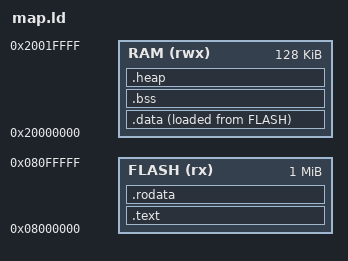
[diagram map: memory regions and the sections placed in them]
/*
 * ============================================================================
 * LINKER SCRIPT FOR BARE-METAL STM32F407 C++ OPENPLC HARDWARE
 * ============================================================================
 */

/* Entry Point definition: Instructs the toolchain where execution starts at boot */
/*ENTRY(Reset_Handler)*/

/* Specify the physical memory layout of the STM32F407VGT6 microcontroller :
 * 1. FLASH (rx) : Read-Only and Executable memory. Holds your code, constants, and tables.
 * 2. RAM (rwx)   : Read-Write and Executable memory. Holds global variables, stack, and heap.
 */
MEMORY
{
  FLASH (rx)      : ORIGIN = 0x08000000, LENGTH = 1024K
  RAM (rwx)       : ORIGIN = 0x20000000, LENGTH = 128K
}

SECTIONS
{
  /* 
   * ==========================================================================
   * 1. THE EXECUTABLE CODE SECTION (.text)
   * ==========================================================================
   * This section targets FLASH memory. It must strictly contain executable
   * code patterns to avoid security / MPU faults if Execute-Only permissions are enforced.
   */
  .text :
  {
    . = ALIGN(4); /* Pads memory layout to align perfectly with the 32-bit hardware bus */
    
    /* The Vector Table MUST sit at the very front of Flash memory (Address 0x08000000) */
    *(.vectors*) 
    
    /* Main application machine code compiled from all your .cpp assembly pools */
    *(.text*) 
    
    . = ALIGN(4);
  } > FLASH

  /* 
   * ==========================================================================
   * 2. THE READ-ONLY DATA SECTION (.rodata)
   * ==========================================================================
   * This section isolates data variables from code blocks, making it highly secure.
   */
  .rodata :
  {
    . = ALIGN(4);
    
    /* Holds string literals, constant structures, and look-up parameters */
    *(.rodata*) 
    
    /*
     * ------------------------------------------------------------------------
     * C++ RUNTIME OBJECT CONSTRUCTOR ARRAYS (CRITICAL FOR OPENPLC)
     * ------------------------------------------------------------------------
     * When your startup.s file executes 'BL __libc_init_array', the routine loops
     * through the addresses bounded between '__init_array_start' and '__init_array_end'.
     * It runs the constructors for your global 'config.INSTANCE0' variables 
     * generated by OpenPLC, clearing out uninitialized junk RAM before main() starts.
     */
    . = ALIGN(4);
    PROVIDE(__preinit_array_start = .);
    *(.preinit_array*)
    PROVIDE(__preinit_array_end = .);
    
    . = ALIGN(4);
    PROVIDE(__init_array_start = .);
    *(SORT(.init_array.*))
    *(.init_array*)
    PROVIDE(__init_array_end = .);

    /*
     * ------------------------------------------------------------------------
     * C++ EXCEPTION HANDLING & STACK UNWINDING TABLES
     * ------------------------------------------------------------------------
     * - .ARM.extab: The bytecode "cleanup manual" for unpacking the registers safely.
     * - .gnu.linkonce: Discards duplicate cleanup blocks across different compiled objects.
     * - .ARM.exidx: The Table of Contents. Links instruction addresses to extab recipes.
     * - __exidx_start / __exidx_end: Essential boundaries read by the library. 
     *   Declaring these completely satisfies the "undefined reference to get_eit_entry" error.
     
     * CRITICAL HINT: The Index Table itself MUST be 8-byte aligned!
     * We change this to ALIGN(8) to follow the strict ARM Exception ABI.
     */
    . = ALIGN(8);
    *(.ARM.extab* .gnu.linkonce.armextab.*)
    
    __exidx_start = .;
    *(.ARM.exidx* .gnu.linkonce.armexidx.*)
    __exidx_end = .;
    
    . = ALIGN(4);
  } > FLASH

  /* 
   * ==========================================================================
   * 3. INITIALIZED GLOBAL DATA SECTION (.data)
   * ==========================================================================
   * Variables defined with an initial value (e.g., int cyclic_counter = 5;).
   * - In Flash: Holds the permanent initial static values.
   * - In RAM: This is where the CPU reads and modifies them at runtime.
   * Your startup.s must copy data from '_sidata' (Flash) to '_sdata' (RAM).
   */
  _sidata = LOADADDR(.data); /* Fetch the literal address inside FLASH where data presets sleep */

  .data :
  {
    . = ALIGN(4);
    _sdata = .;        /* Target marker used by startup.s to start copying data into RAM */
    *(.data*)          /* Collects all initialized variables */
    . = ALIGN(4);
    _edata = .;        /* Target marker used by startup.s to know when to stop copying */
  } > RAM AT > FLASH   /* Allocates runtime mapping to RAM, but stores the payload inside FLASH */

  /* 
   * ==========================================================================
   * 4. UNINITIALIZED DATA SECTION (.bss)
   * ==========================================================================
   * Variables defined without any starting value (e.g., int motor_speed;).
   * Your startup.s must find everything between '_sbss' and '_ebss' inside RAM
   * and wipe those addresses completely clean to zero (0) before launching code loops.
   */
  .bss :
  {
    . = ALIGN(4);
    __bss_start__ = .;         /* Marker used by startup.s to begin clearing RAM memory to zero */
    *(.bss*)
    *(COMMON)          /* Pulls in loose, globally scattered uninitialized variables */
    . = ALIGN(4);
    __bss_end__ = .;         /* Marker used by startup.s to finish clearing RAM memory */
  } > RAM

   /* 
   * ==========================================================================
   * 5. HEAP & STACK BOUNDARY DEFINITIONS
   * ==========================================================================
   * RUNTIME HEAP WORKSPACE CONTROL GENERATION (_end)
   * This variable provides a dynamic landmark immediately following all variables.
   * Your '_sbrk_r' allocation stub references this location to establish where the 
   * C++ Heap starts growing upward, ensuring allocations safely monitor boundaries 
   * without colliding with the downward-growing Stack Pointer.
   */
  .heap (NOLOAD) : 
  {
    . = ALIGN(8);      /* 8-byte alignment required for modern C++ double/64-bit data */
    _end = .;          /* Used by your _sbrk_r() stub as the start of the Heap space */
    PROVIDE(end = .);  /* Standard naming alias used by some compiler libraries */
    . = ALIGN(8);  
  } > RAM
/* Closes SECTIONS block */

/* 
 * Calculate the exact starting address for the Main Stack Pointer (MSP).
 * ARM Cortex-M processors require the Stack Pointer to be 8-byte aligned.
 * Since LENGTH(RAM) ends exactly at an 8-byte boundary, do NOT subtract 4.
 */
__StackTop = ORIGIN(RAM) + LENGTH(RAM);
PROVIDE(_estack = __StackTop);
}
